# nrf9160 register map
Vendor: Nordic Semiconductor; Series: nrf91; File version: 1
CPU: CM33 r0p4, little endian, MPU, FPU, 3 interrupt priority bits, 69 interrupts
Registers are 32-bit, read-write, reset 0x0 unless marked. A register's access mark holds for its fields unless they carry their own. Offsets are from the block's base; [hi:lo] are bit positions; 'fields as' and 'values as' point back to an identical list.

## FPU_NS — FPU 0
Base 0x4002C000
Same registers: FPU_S 0x5002C000

## KMU_NS — Key management unit 0
Base 0x40039000
Same registers: KMU_S 0x50039000
0x00 TASKS_PUSH_KEYSLOT wo — Push a key slot over secure APB
  [0] TASKS_PUSH_KEYSLOT
    1=Trigger task
0x100 EVENTS_KEYSLOT_PUSHED — Key slot successfully pushed over secure APB
  [0] EVENTS_KEYSLOT_PUSHED
    0=NotGenerated (Event not generated); 1=Generated (Event generated)
0x104 EVENTS_KEYSLOT_REVOKED — Key slot has been revoked and cannot be tasked for selection
  [0] EVENTS_KEYSLOT_REVOKED
    values as EVENTS_KEYSLOT_PUSHED.EVENTS_KEYSLOT_PUSHED
0x108 EVENTS_KEYSLOT_ERROR — No key slot selected, no destination address defined, or error during push operation
  [0] EVENTS_KEYSLOT_ERROR
    values as EVENTS_KEYSLOT_PUSHED.EVENTS_KEYSLOT_PUSHED
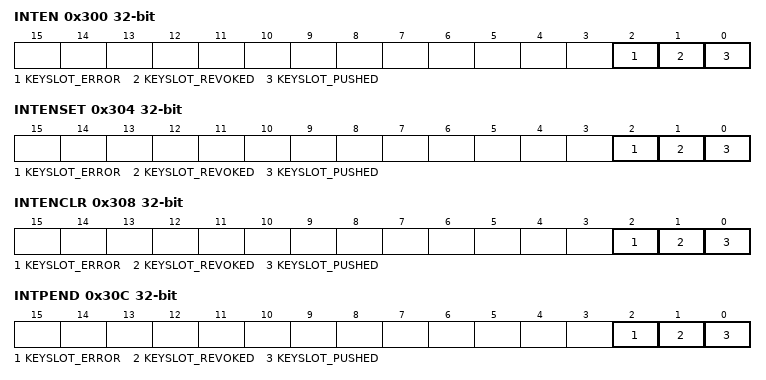
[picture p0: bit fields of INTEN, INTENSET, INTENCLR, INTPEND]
0x300 INTEN — Enable or disable interrupt
  [all] fields
    0=Disabled; 1=Enabled
  [2] KEYSLOT_ERROR — Enable or disable interrupt for event KEYSLOT_ERROR
  [1] KEYSLOT_REVOKED — Enable or disable interrupt for event KEYSLOT_REVOKED
  [0] KEYSLOT_PUSHED — Enable or disable interrupt for event KEYSLOT_PUSHED
0x304 INTENSET — Enable interrupt
  [all] fields
    on read: 0=Disabled (Read: Disabled); 1=Enabled (Read: Enabled) | on write: 1=Set (Enable)
  [2] KEYSLOT_ERROR — Write '1' to enable interrupt for event KEYSLOT_ERROR
  [1] KEYSLOT_REVOKED — Write '1' to enable interrupt for event KEYSLOT_REVOKED
  [0] KEYSLOT_PUSHED — Write '1' to enable interrupt for event KEYSLOT_PUSHED
0x308 INTENCLR — Disable interrupt
  [all] fields
    on read: 0=Disabled (Read: Disabled); 1=Enabled (Read: Enabled) | on write: 1=Clear (Disable)
  [2] KEYSLOT_ERROR — Write '1' to disable interrupt for event KEYSLOT_ERROR
  [1] KEYSLOT_REVOKED — Write '1' to disable interrupt for event KEYSLOT_REVOKED
  [0] KEYSLOT_PUSHED — Write '1' to disable interrupt for event KEYSLOT_PUSHED
0x30C INTPEND ro — Pending interrupts
  [all] fields
    on read: 0=NotPending (Read: Not pending); 1=Pending (Read: Pending)
  [2] KEYSLOT_ERROR — Read pending status of interrupt for event KEYSLOT_ERROR
  [1] KEYSLOT_REVOKED — Read pending status of interrupt for event KEYSLOT_REVOKED
  [0] KEYSLOT_PUSHED — Read pending status of interrupt for event KEYSLOT_PUSHED
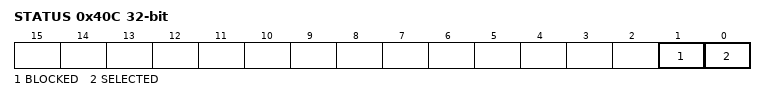
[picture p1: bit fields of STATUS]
0x40C STATUS ro — Status bits for KMU operation
  [1] BLOCKED — Violation status
    0=Disabled (No access violation detected); 1=Enabled (Access violation detected and blocked)
  [0] SELECTED — Key slot ID successfully selected by the KMU
    0=Disabled (No key slot ID selected by KMU); 1=Enabled (Key slot ID successfully selected by KMU)
0x500 SELECTKEYSLOT — Select key slot to be read over AHB or pushed over secure APB when TASKS_PUSH_KEYSLOT is started
  [7:0] ID — Select key slot ID to be read over AHB, or pushed over secure APB, when TASKS_PUSH_KEYSLOT is started NOTE: ID=0 is not a valid key slot ID. The 0 ID should be used when the KMU is idle or not in use NOTE: Index N in UICR->KEYSLOT.KEY[N] and UICR->KEYSLOT.CONFIG[N] corresponds to KMU key slot ID=N+1

## NVMC_NS — Non-volatile memory controller 0
Base 0x40039000; alternate view of KMU_NS
Same registers: NVMC_S 0x50039000 (alternate view of KMU_S)
0x400 READY ro reset 0x1 — Ready flag
  [0] READY — NVMC is ready or busy
    0=Busy (NVMC is busy (on-going write or erase operation)); 1=Ready (NVMC is ready)
0x408 READYNEXT ro reset 0x1 — Ready flag
  [0] READYNEXT — NVMC can accept a new write operation
    0=Busy (NVMC cannot accept any write operation); 1=Ready (NVMC is ready)
0x504 CONFIG — Configuration register
  [2:0] WEN — Program memory access mode. It is strongly recommended to only activate erase and write modes when they are actively used. Enabling write or erase will invalidate the cache and keep it invalidated.
    0=Ren (Read only access); 1=Wen (Write enabled); 2=Een (Erase enabled); 4=PEen (Partial erase enabled)
0x50C ERASEALL wo — Register for erasing all non-volatile user memory
  [0] ERASEALL — Erase all non-volatile memory including UICR registers. Note that erasing must be enabled by setting CONFIG.WEN = Een before the non-volatile memory can be erased.
    0=NoOperation; 1=Erase (Start chip erase)
0x51C ERASEPAGEPARTIALCFG reset 0xA — Register for partial erase configuration
  [6:0] DURATION — Duration of the partial erase in milliseconds
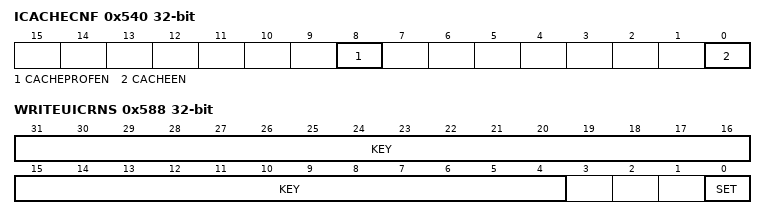
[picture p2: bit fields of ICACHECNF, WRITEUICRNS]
0x540 ICACHECNF — I-code cache configuration register
  [8] CACHEPROFEN — Cache profiling enable
    0=Disabled (Disable cache profiling); 1=Enabled (Enable cache profiling)
  [0] CACHEEN — Cache enable
    0=Disabled (Disable cache. Invalidates all cache entries.); 1=Enabled (Enable cache)
0x548 IHIT — I-code cache hit counter
  [31:0] HITS — Number of cache hits Write zero to clear
0x54C IMISS — I-code cache miss counter
  [31:0] MISSES — Number of cache misses Write zero to clear
0x584 CONFIGNS — Unspecified
  [1:0] WEN — Program memory access mode. It is strongly recommended to only activate erase and write modes when they are actively used. Enabling write or erase will invalidate the cache and keep it invalidated.
    0=Ren (Read only access); 1=Wen (Write enabled); 2=Een (Erase enabled)
0x588 WRITEUICRNS wo — Non-secure APPROTECT enable register
  [31:4] KEY — Key to write in order to validate the write operation
    0xAFBE5A7=Keyvalid (Key value)
  [0] SET — Allow non-secure code to set APPROTECT
    1=Set (Set value)
